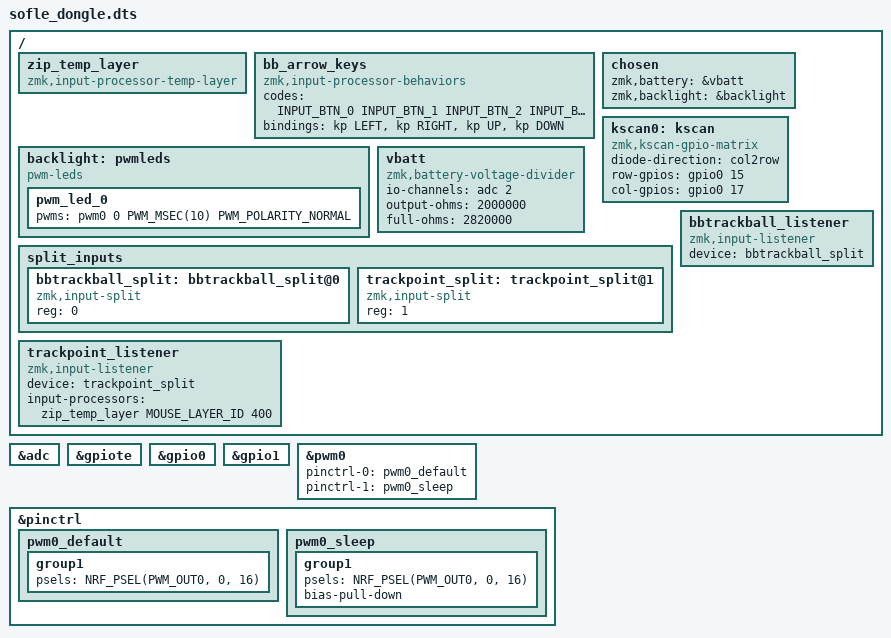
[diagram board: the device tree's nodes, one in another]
/*
 * Copyright (c) 2023 ZitaoTech
 *
 * SPDX-License-Identifier: MIT
 */

#include "sofle_dongle.dtsi"
#include <input/processors.dtsi>
#include <zephyr/dt-bindings/input/input-event-codes.h>
#include <dt-bindings/zmk/keys.h>

#define MOUSE_LAYER_ID 2

/* 定义临时层切换 input-processor */
/ {
    zip_temp_layer: zip_temp_layer {
        compatible = "zmk,input-processor-temp-layer";
        #input-processor-cells = <2>;
    };

    /* 定义轨迹球方向键转换处理器（使用虚拟按钮）*/
    bb_arrow_keys: bb_arrow_keys {
        compatible = "zmk,input-processor-behaviors";
        #input-processor-cells = <0>;
        /* 映射按钮事件到方向键 */
        codes = <INPUT_BTN_0 INPUT_BTN_1 INPUT_BTN_2 INPUT_BTN_3>;
        bindings = <&kp LEFT>, <&kp RIGHT>, <&kp UP>, <&kp DOWN>;
    };
};

/ {
    chosen {
        zmk,battery = &vbatt;
        zmk,backlight = &backlight;
    };

    backlight: pwmleds {
        compatible = "pwm-leds";
        pwm_led_0 {
            pwms = <&pwm0 0 PWM_MSEC(10) PWM_POLARITY_NORMAL>;
        };
    };

    kscan0: kscan {
        compatible = "zmk,kscan-gpio-matrix";
        diode-direction = "col2row";
        row-gpios
            = <&gpio0 15 (GPIO_ACTIVE_HIGH | GPIO_PULL_DOWN)>
            ;
        col-gpios
            = <&gpio0 17  GPIO_ACTIVE_HIGH>
            ;
    };


    vbatt: vbatt {
        compatible = "zmk,battery-voltage-divider";
        io-channels = <&adc 2>;
        output-ohms = <2000000>;
        full-ohms = <2820000>;  // 2000000 + 820000
    };
};


/ {
    split_inputs {
        #address-cells = <1>;
        #size-cells = <0>;

        bbtrackball_split: bbtrackball_split@0 {
            compatible = "zmk,input-split";
            reg = <0>;
        };
    };

};


/ {
    split_inputs {
        #address-cells = <1>;
        #size-cells = <0>;

        trackpoint_split: trackpoint_split@1 {
            compatible = "zmk,input-split";
            reg = <1>;
        };
    };

};


/ {
    trackpoint_listener: trackpoint_listener {
        compatible = "zmk,input-listener";
        status = "disabled";
        device = <&trackpoint_split>;
    };
    bbtrackball_listener: bbtrackball_listener {
        compatible = "zmk,input-listener";
        status = "disabled";
        device = <&bbtrackball_split>;
    };
};

/* 启用 trackpoint_listener，并绑定临时层切换处理器 */
&trackpoint_listener {
    status = "okay";
    input-processors = <&zip_temp_layer MOUSE_LAYER_ID 400>;
};

/* 启用 bbtrackball_listener，不使用任何处理器，直接发送按键事件 */
&bbtrackball_listener {
    status = "okay";
    /* 不绑定 input-processors，让 INPUT_KEY 事件直接传输到主机 */
};

&adc {
    status = "okay";
};

&gpiote {
    status = "okay";
};

&gpio0 {
    status = "okay";
};

&gpio1 {
    status = "okay";
};

&pwm0 {
    status = "okay";
    pinctrl-0 = <&pwm0_default>;
    pinctrl-1 = <&pwm0_sleep>;
    pinctrl-names = "default", "sleep";
};




&pinctrl {

    pwm0_default:pwm0_default{
        group1{
            psels = <NRF_PSEL(PWM_OUT0, 0, 16)>; // Backlight for backlight.c unreal
        };
    };

    pwm0_sleep: pwm0_sleep {
        group1 {
            psels = <NRF_PSEL(PWM_OUT0, 0, 16)>;
            bias-pull-down;
        };
    };

};

/*
/ {
    input_processors {
        zip_right_click_trigger_paste: zip_right_click_trigger_paste {
            compatible = "zmk,input-processor-behaviors";
            #input-processor-cells = <0>;
            codes    = <INPUT_BTN_1>;
            bindings = <&kp A>;
        };
    };
}; */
